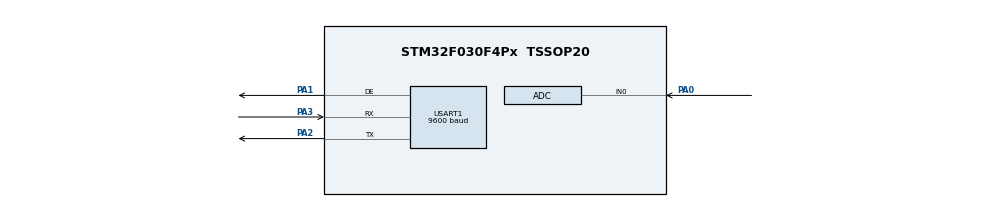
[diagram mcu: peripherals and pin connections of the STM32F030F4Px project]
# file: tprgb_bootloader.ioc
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Mcu.Family=STM32F0
Mcu.Name=STM32F030F4Px
Mcu.Package=TSSOP20
NVIC.ADC1_IRQn=true\:0\:0\:false\:false\:true\:true\:true\:true
NVIC.USART1_IRQn=true\:0\:0\:false\:false\:true\:true\:true\:true
PA0.Mode=IN0
PA0.Signal=ADC_IN0
PA1.Mode=Hardware Flow Control (RS485)
PA1.Signal=USART1_DE
PA13.Mode=Serial_Wire
PA13.Signal=SYS_SWDIO
PA14.Mode=Serial_Wire
PA14.Signal=SYS_SWCLK
PA2.Mode=Asynchronous
PA2.Signal=USART1_TX
PA3.Mode=Asynchronous
PA3.Signal=USART1_RX
ProjectManager.HeapSize=0x200
ProjectManager.StackSize=0x400
ProjectManager.TargetToolchain=STM32CubeIDE
USART1.BaudRate=9600
USART1.VirtualMode-Asynchronous=VM_ASYNC
USART1.VirtualMode-Hardware\ Flow\ Control\ (RS485)=VM_ASYNC
board=custom

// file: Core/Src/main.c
/* USER CODE BEGIN Header */
/**
  ******************************************************************************
  * @file           : main.c
  * @brief          : Main program body
  ******************************************************************************
  * @attention
  *
  * Copyright (c) 2025 STMicroelectronics.
  * All rights reserved.
  *
  * This software is licensed under terms that can be found in the LICENSE file
  * in the root directory of this software component.
  * If no LICENSE file comes with this software, it is provided AS-IS.
  *
  ******************************************************************************
  */
/* USER CODE END Header */
#include "main.h"

/* USER CODE BEGIN Includes */
#include "modbus.h"
/* USER CODE END Includes */

void SystemClock_Config(void);
static void MX_GPIO_Init(void);
static void MX_ADC_Init(void);
static void MX_USART1_UART_Init(void);

/* USER CODE BEGIN 0 */
volatile mb_packet *mbp;
/* USER CODE END 0 */

int main(void)
{

  /* MCU Configuration--------------------------------------------------------*/

  /* Reset of all peripherals, Initializes the Flash interface and the Systick. */
  LL_APB1_GRP2_EnableClock(LL_APB1_GRP2_PERIPH_SYSCFG);
  LL_APB1_GRP1_EnableClock(LL_APB1_GRP1_PERIPH_PWR);

  /* SysTick_IRQn interrupt configuration */
  NVIC_SetPriority(SysTick_IRQn, 3);

  /* Configure the system clock */
  SystemClock_Config();

  /* Initialize all configured peripherals */
  MX_GPIO_Init();
  MX_ADC_Init();
  MX_USART1_UART_Init();
  /* USER CODE BEGIN 2 */
  mb_init();
  /* USER CODE END 2 */

  /* Infinite loop */
  /* USER CODE BEGIN WHILE */
  while (1)
  {
	  if (mb_can_evalueate_packet) {
		  if (mb_crc_is_ok()) {
			  mbp = mb_packet_eval();
		  }
	  }
    /* USER CODE END WHILE */

  }
}

void SystemClock_Config(void)
{
  LL_FLASH_SetLatency(LL_FLASH_LATENCY_0);
  while(LL_FLASH_GetLatency() != LL_FLASH_LATENCY_0)
  {
  }
  LL_RCC_HSI_Enable();

   /* Wait till HSI is ready */
  while(LL_RCC_HSI_IsReady() != 1)
  {

  }
  LL_RCC_HSI_SetCalibTrimming(16);
  LL_RCC_HSI14_Enable();

   /* Wait till HSI14 is ready */
  while(LL_RCC_HSI14_IsReady() != 1)
  {

  }
  LL_RCC_HSI14_SetCalibTrimming(16);
  LL_RCC_SetAHBPrescaler(LL_RCC_SYSCLK_DIV_1);
  LL_RCC_SetAPB1Prescaler(LL_RCC_APB1_DIV_1);
  LL_RCC_SetSysClkSource(LL_RCC_SYS_CLKSOURCE_HSI);

   /* Wait till System clock is ready */
  while(LL_RCC_GetSysClkSource() != LL_RCC_SYS_CLKSOURCE_STATUS_HSI)
  {

  }
  LL_Init1msTick(8000000);
  LL_SetSystemCoreClock(8000000);
  LL_RCC_HSI14_EnableADCControl();
  LL_RCC_SetUSARTClockSource(LL_RCC_USART1_CLKSOURCE_PCLK1);
}

static void MX_ADC_Init(void)
{

  LL_ADC_InitTypeDef ADC_InitStruct = {0};
  LL_ADC_REG_InitTypeDef ADC_REG_InitStruct = {0};

  LL_GPIO_InitTypeDef GPIO_InitStruct = {0};

  /* Peripheral clock enable */
  LL_APB1_GRP2_EnableClock(LL_APB1_GRP2_PERIPH_ADC1);

  LL_AHB1_GRP1_EnableClock(LL_AHB1_GRP1_PERIPH_GPIOA);
  /**ADC GPIO Configuration
  PA0   ------> ADC_IN0
  */
  GPIO_InitStruct.Pin = LL_GPIO_PIN_0;
  GPIO_InitStruct.Mode = LL_GPIO_MODE_ANALOG;
  GPIO_InitStruct.Pull = LL_GPIO_PULL_NO;
  LL_GPIO_Init(GPIOA, &GPIO_InitStruct);

  /* ADC interrupt Init */
  NVIC_SetPriority(ADC1_IRQn, 0);
  NVIC_EnableIRQ(ADC1_IRQn);

  /** Configure Regular Channel
  */
  LL_ADC_REG_SetSequencerChAdd(ADC1, LL_ADC_CHANNEL_0);

  /** Configure the global features of the ADC (Clock, Resolution, Data Alignment and number of conversion)
  */
  ADC_InitStruct.Clock = LL_ADC_CLOCK_ASYNC;
  ADC_InitStruct.Resolution = LL_ADC_RESOLUTION_12B;
  ADC_InitStruct.DataAlignment = LL_ADC_DATA_ALIGN_RIGHT;
  ADC_InitStruct.LowPowerMode = LL_ADC_LP_MODE_NONE;
  LL_ADC_Init(ADC1, &ADC_InitStruct);
  ADC_REG_InitStruct.TriggerSource = LL_ADC_REG_TRIG_SOFTWARE;
  ADC_REG_InitStruct.SequencerDiscont = LL_ADC_REG_SEQ_DISCONT_DISABLE;
  ADC_REG_InitStruct.ContinuousMode = LL_ADC_REG_CONV_SINGLE;
  ADC_REG_InitStruct.DMATransfer = LL_ADC_REG_DMA_TRANSFER_LIMITED;
  ADC_REG_InitStruct.Overrun = LL_ADC_REG_OVR_DATA_PRESERVED;
  LL_ADC_REG_Init(ADC1, &ADC_REG_InitStruct);
  LL_ADC_REG_SetSequencerScanDirection(ADC1, LL_ADC_REG_SEQ_SCAN_DIR_FORWARD);
  LL_ADC_SetSamplingTimeCommonChannels(ADC1, LL_ADC_SAMPLINGTIME_1CYCLE_5);

}

static void MX_USART1_UART_Init(void)
{

  LL_USART_InitTypeDef USART_InitStruct = {0};

  LL_GPIO_InitTypeDef GPIO_InitStruct = {0};

  /* Peripheral clock enable */
  LL_APB1_GRP2_EnableClock(LL_APB1_GRP2_PERIPH_USART1);

  LL_AHB1_GRP1_EnableClock(LL_AHB1_GRP1_PERIPH_GPIOA);
  /**USART1 GPIO Configuration
  PA1   ------> USART1_DE
  PA2   ------> USART1_TX
  PA3   ------> USART1_RX
  */
  GPIO_InitStruct.Pin = LL_GPIO_PIN_1;
  GPIO_InitStruct.Mode = LL_GPIO_MODE_ALTERNATE;
  GPIO_InitStruct.Speed = LL_GPIO_SPEED_FREQ_HIGH;
  GPIO_InitStruct.OutputType = LL_GPIO_OUTPUT_PUSHPULL;
  GPIO_InitStruct.Pull = LL_GPIO_PULL_NO;
  GPIO_InitStruct.Alternate = LL_GPIO_AF_1;
  LL_GPIO_Init(GPIOA, &GPIO_InitStruct);

  GPIO_InitStruct.Pin = LL_GPIO_PIN_2;
  GPIO_InitStruct.Mode = LL_GPIO_MODE_ALTERNATE;
  GPIO_InitStruct.Speed = LL_GPIO_SPEED_FREQ_HIGH;
  GPIO_InitStruct.OutputType = LL_GPIO_OUTPUT_PUSHPULL;
  GPIO_InitStruct.Pull = LL_GPIO_PULL_NO;
  GPIO_InitStruct.Alternate = LL_GPIO_AF_1;
  LL_GPIO_Init(GPIOA, &GPIO_InitStruct);

  GPIO_InitStruct.Pin = LL_GPIO_PIN_3;
  GPIO_InitStruct.Mode = LL_GPIO_MODE_ALTERNATE;
  GPIO_InitStruct.Speed = LL_GPIO_SPEED_FREQ_HIGH;
  GPIO_InitStruct.OutputType = LL_GPIO_OUTPUT_PUSHPULL;
  GPIO_InitStruct.Pull = LL_GPIO_PULL_NO;
  GPIO_InitStruct.Alternate = LL_GPIO_AF_1;
  LL_GPIO_Init(GPIOA, &GPIO_InitStruct);

  /* USART1 interrupt Init */
  NVIC_SetPriority(USART1_IRQn, 0);
  NVIC_EnableIRQ(USART1_IRQn);

  USART_InitStruct.BaudRate = 9600;
  USART_InitStruct.DataWidth = LL_USART_DATAWIDTH_8B;
  USART_InitStruct.StopBits = LL_USART_STOPBITS_1;
  USART_InitStruct.Parity = LL_USART_PARITY_NONE;
  USART_InitStruct.TransferDirection = LL_USART_DIRECTION_TX_RX;
  USART_InitStruct.HardwareFlowControl = LL_USART_HWCONTROL_NONE;
  USART_InitStruct.OverSampling = LL_USART_OVERSAMPLING_16;
  LL_USART_Init(USART1, &USART_InitStruct);
  LL_USART_EnableDEMode(USART1);
  LL_USART_SetDESignalPolarity(USART1, LL_USART_DE_POLARITY_HIGH);
  LL_USART_SetDEAssertionTime(USART1, 0);
  LL_USART_SetDEDeassertionTime(USART1, 0);
  LL_USART_ConfigAsyncMode(USART1);
  LL_USART_Enable(USART1);

}

static void MX_GPIO_Init(void)
{

  /* GPIO Ports Clock Enable */
  LL_AHB1_GRP1_EnableClock(LL_AHB1_GRP1_PERIPH_GPIOA);

}

void Error_Handler(void)
{
  __disable_irq();
  while (1)
  {
  }
}
